# FSITX1_CFG register map
Vendor: Texas Instruments
Peripheral module from a debugger description file (folder am243x).
Registers are 16-bit, read-write, reset values left out (the file's numbers can be read two ways) unless marked. A register's access mark holds for its fields unless they carry their own. Offsets are as the file gives them; lines under a group give offsets from that group; [hi:lo] are bit positions; {n}, {i} and the like mark numbered series; 'fields as' and 'values as' point back to an identical list; <NAME> marks a mode.

## FSITX1_CFG
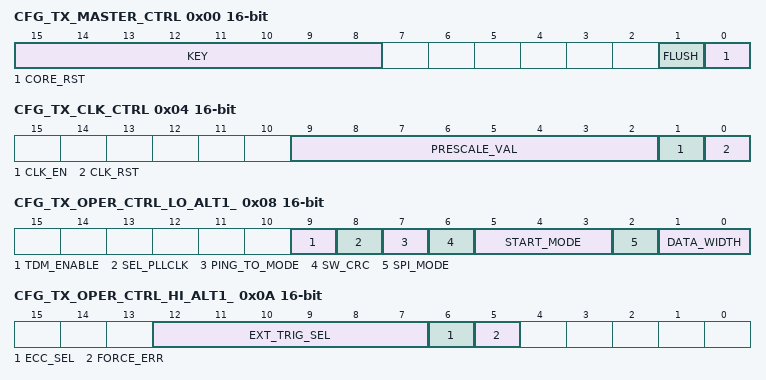
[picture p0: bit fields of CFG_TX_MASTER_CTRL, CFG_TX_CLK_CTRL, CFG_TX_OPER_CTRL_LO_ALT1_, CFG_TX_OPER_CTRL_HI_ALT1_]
0x00 CFG_TX_MASTER_CTRL access per field — Transmit master control register
  [15:8] KEY wo — Write KeyIn order to write to any bit in this register, 0xA5 must be written to this field at the same time. Otherwise, writes are ignored. The key is cleared immediately after writing, so it must be written again for every change to this register.
  [1] FLUSH rw — Flush Operation Start bitThis bit will cause the transmitter to initiate a flush pattern of a single toggle on the TXD0 and TXD1 followed by five full cycles of TXCLK. This bit should be written only when the CORE_RST bit is 0 and the clock to the Transmitter core is turned on. 0h [R/W] = Clear this bit.1h [R/W] = Setting this bit will Initiate flush sequence. To properly execute a flush sequence, Set FLUSH to 1, wait for five TXCLK cycles then clear FLUSH to 0. Note: The KEY field must contain 0xA5 for any write to this bit to take effect. The software must keep this bit set to 1 for at least five TXCLK cycles before setting it back to 0.
  [0] CORE_RST rw — Transmitter Master Core Reset bitThis bit controls the transmitter master core reset. In order to send any frame, this bit must be cleared. 0h [R/W] = Transmitter core is not in reset and can transmit frames.1h [R/W] = Transmitter core is held in reset. Note: The KEY field must contatin 0xA5 for any write to this bit to take effect.
0x02 CFG_Reserved_1 access not given
0x04 CFG_TX_CLK_CTRL — Transmit clock control register. Protected by LOCK field in TX_LOCK_CTRL register.
  [9:2] PRESCALE_VAL — Clock Divider Prescale ValueThe input clock is divided by this 8-bit value and fed into the transmitter core. This divided clock is the rate at which TXCLK will operate. 0h [R/W] = Reserved1h [R/W] = Input clock /12h [R/W] = Input clock /23h [R/W] = Input clock /34h [R/W] = Input clock /4...FFh [R/W] = Input clock /255 TXCLKIN = Input clock / PRESCALE_VALIn FSI mode: TXCLK = TXCLKIN / 2In SPI mode: TXCLK = TXCLKIN
  [1] CLK_EN — Clock Divider Enable bitThis bit will enable and disable the input clock divider and start the clock to the transmitter core. 0h [R/W] = The input clock divider is not enabled and the clock is not connected to the transmitter core.1h [R/W] = The input clock to the transmitter core is being divided by the PRESCALE_VAL and enabled.
  [0] CLK_RST — Clock Divider Reset bitThis bit will reset the clock counter in the clock divider. 0h [R/W] = The clock divider is set based on the value in PRESCALE_VAL. The input clock will be divided by PRESCALE_VAL if CLK_EN is set.1h [R/W] = The clock divider will be reset to 0 and will stay reset until software writes a 0 to this bit.
0x06 CFG_Reserved_2 access not given
0x08 CFG_TX_OPER_CTRL_LO_ALT1_ — Transmit operation control register low. Protected by LOCK field in TX_LOCK_CTRL register.
  [9] TDM_ENABLE — Transmit TDM Mode Enable bit.This bit enables the TDM Mode for multi-slave TDM operation. 0h [R/W] Transmit TDM Mode is not enabled.1h [R/W] Transmit TDM Mode is enabled.
  [8] SEL_PLLCLK — Input Clock Select bitThis bit selects the input clock source for the transmitter core. 0h [R/W] = SYSCLK is the source of the transmitter clock into the clock prescaler.1h [R/W] = PLLRAWCLK is the source of the transmitter core clock into the clock prescaler.
  [7] PING_TO_MODE — Ping Counter Reset Mode Select bitThis bit selects when the ping counter will reset. 0h [R/W] = The ping counter will reset and restart only on hardware initiated ping frames, when ping counter has timed out.1h [R/W] = The ping counter will reset and restart on any software initiated frame as well as a ping counter timeout
  [6] SW_CRC — CRC Source Select bitThis bit selects the source of the CRC value that is transmitted. 0h [R/W] = The transmitted CRC value is computed by hardware.1h [R/W] = The transmitted CRC value is sourced from the value programmed in the TX_USER_CRC register.
  [5:3] START_MODE — Transmission Start Mode Select bitThese bits select the method by which a new frame transmission is started. 0h [R/W] = Only a software write to TX_FRAME_CTRL.START initiate a new transmission.1h [R/W] = The configured external trigger will initiate a new transmission.2h [R/W] = Either writing to TX_FRAME_CTRL.START or the TX_FRAME_TAG_UDATA register will initiate a new transmission. All other combinations of bits are illegal and reserved for future use.
  [2] SPI_MODE — SPI Mode Select bitThis bit enables and disables SPI compatibility mode. 0h [R/W] = FSI is in normal mode of operation.1h [R/W] = FSI is operating in SPI compatibility mode.
  [1:0] DATA_WIDTH — Transmit Data Width Select bitsThese bits define the number of data lines used by the transmitter. 0h [R/W] = Data will be transmitted on one data line [TXD0]1h [R/W] = Data will be transmitted on two data lines [TXD0 and TXD1]. The format of the data is described in the preceeding chapter.2h, 3h [R/W] = Reserved
0x0A CFG_TX_OPER_CTRL_HI_ALT1_ — Transmit operation control register high. Protected by LOCK field in TX_LOCK_CTRL register.
  [12:7] EXT_TRIG_SEL — External Trigger Select bitThese bits define which of the 32 external inputs will be used as the source for the external input trigger. 00h [R/W] = Trigger 1 is the source.01h [R/W] = Trigger 2 is the source.02h [R/W] = Trigger 3 is the source....3Fh [R/W] = Trigger 64 is the source.
  [6] ECC_SEL — ECC Data Width Select bitThis bit selects between 16-bit and 32-bit ECC computation. 0h [R/W] = 32-bit ECC is used.1h [R/W] = 16-bit ECC is used.
  [5] FORCE_ERR — Error Frame Force bitThis bit will force the the CRC value of the transmitted data frame to 0 whenever there is a buffer overrun or underrun condition. This can be used to force a corrupted CRC as the data is not guaranteed to be reliable. The receiver will treat the data as invalid and can handle this as needed.Note: DO NOT use FORCE_ERR if using the SW CRC mode [FSI Transmit]. 0h [R/W] = The CRC will not be forced to 0.1h [R/W] = The CRC will be forced to 0 in a buffer overrun or underrun condition.
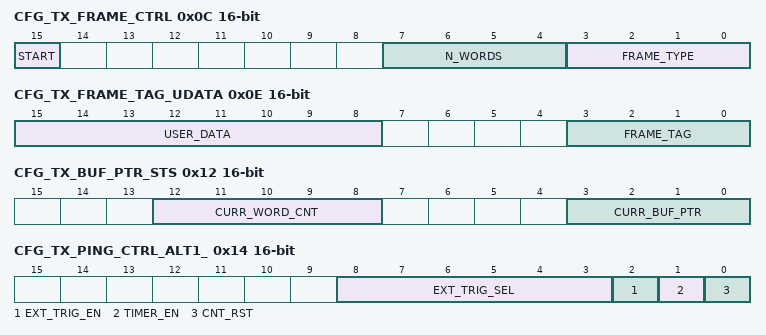
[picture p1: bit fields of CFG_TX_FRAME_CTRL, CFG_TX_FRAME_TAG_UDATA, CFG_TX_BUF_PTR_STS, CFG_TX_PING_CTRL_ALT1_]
0x0C CFG_TX_FRAME_CTRL — Transmit frame control register
  [15] START — Start Transmission bitThis bit will cause the FSI to start transmitting the next frame. 0h [R/W] = Writing a 0 to this bit will have no effect.1h [R/W] = Start the next transmission. This bit will be cleared by hardware.
  [7:4] N_WORDS — Number of Words to be TransmittedThis field defines the number of words which will be transmitted in a DATA_N_WORD frame. This is a user-defined field that must match the corresponding field in the receiver. Set this bitfield to be one less than the number of words to be transmitted. 0h [R/W] = 1 data word frame [16-bit data].1h [R/W] = 2 data word frame [32-bit data]...Fh [R/W] = 16 data word frame [256-bit data].
  [3:0] FRAME_TYPE — Transmit Frame TypeThis field determines the type of frame that will be transmitted next. 0000b [R/W] = Ping Frame. This frame can be sent either by software or automatically by hardware.0100b [R/W] = DATA_1_WORD Frame. One word data frame [16-bit data].0101b [R/W] = DATA_2_WORD Frame. Two word data frame [32-bit data].0110b [R/W] = DATA_4_WORD Frame. Four word data frame [64-bit data]. 0111b [R/W] = DATA_6_WORD Frame. Six word data frame [96-bit data].0011b [R/W] = DATA_N_WORD Frame. The N_WORDS field will determine the number of words [1 to 16] to be sent. Both the transmitter and receiver must have the same value programmed.1111b [R/W] = Error Frame. This frame can be used during error conditions or any condition where the transmitter wants to notify the receiver of a high priorty status. However, the user software is at liberty to use this for any purpose. 0001b, 0010b, and 1000b through 1110b are Reserved and should not be used.
0x0E CFG_TX_FRAME_TAG_UDATA — Transmit frame tag and user data register
  [15:8] USER_DATA — User Data bitsThis is a user-defined value that will be loaded into the the user data phase of the frame. This 8-bit value can be used by the receiver for any application need. This value will not impact any hardware behavior.
  [3:0] FRAME_TAG — This will be used only for software initiated transmissions.Frame tag bitsThis is a user-defined value that will be loaded into the frame tag phase of the next transmission. The receiver may use the frame tag for any application need. This value will not impact any hardware behavior For external triggers do not use this register. Use the TX_PING_TAG register instead.
0x10 CFG_TX_BUF_PTR_LOAD — Transmit buffer pointer control load register
  [3:0] BUF_PTR_LOAD — Buffer Pointer Load bitsThese bits are used to force the transmit buffer pointer to a desired index within the transmit buffer. The next transmission will begin picking data from this index and increment appropriately. This value will be reflected in TX_BUF_PTR_STS only after a minimum 3 SYSCLK cycles + 3 TXCLK cycles. This value should not be written while there is an active transmission as it may corrupt the ongoing frame or other undefined behavior.
0x12 CFG_TX_BUF_PTR_STS ro — Transmit buffer pointer control status register
  [12:8] CURR_WORD_CNT — Words Remaining in the transmit buffer This value indicates the number of words present in the data buffer which have not yet been transmitted. This value is only valid when there is no active transmission. Note: This value will not be valid if there is a buffer overrun or underrun condition.
  [3:0] CURR_BUF_PTR — Current Buffer Pointer IndexThis bitfield will show the current index of the buffer pointer. This value is only valid when there is no active transmission.
0x14 CFG_TX_PING_CTRL_ALT1_ — Transmit ping control register. Protected by LOCK field in TX_LOCK_CTRL register.
  [8:3] EXT_TRIG_SEL — External Trigger Select bitsThis bitfield will select one of the 64 external trigger inputs to as the source to generate a ping frame. A ping frame will only be generated if the EXT_TRIG_EN bit is set. 0h [R/W] = Trigger 1 will be used to generate a ping frame.1h [R/W] = Trigger 2 will be used to generate a ping frame...3Fh [R/W] = Trigger 64 will be used to generate a ping frame.
  [2] EXT_TRIG_EN — External Trigger Enable bitThis bit will allow the external trigger logic to generate a ping frame. 0h [R/W] = External triggers will not be used to generate ping frames.1h [R/W] = The selected external trigger [selected by EXT_TRIG_SEL bits] will be able to generate a ping frame. The ping timer will be ignored if this bit is set.
  [1] TIMER_EN — Ping Timer Enable bitThis bit will enable the ping timer for generating periodic ping frames. 0h [R/W] = The ping timer is disabled and will not generate ping frames.1h [R/W] = The ping timer is enabled and can be used to generate ping frames.Once the timer count reaches the value set by the TX_PING_TO_REF register, it will initiate a ping frame transmission. Note: If the ping timer is used, EXT_TRIG_EN should not be set as it will override this function.
  [0] CNT_RST — Ping Counter Reset bitThis bit will reset the the ping counter to 0. This bit will always be read as 0. 0h [R/W] = Writing a 0 to this bit has no effect.1h [R/W] = The ping counter will be reset to 0.
0x16 CFG_TX_PING_TAG — Transmit ping tag register
  [3:0] TAG — Ping Frame TagThis field contains a 4-bit tag which will be sent in any ping frame that is initiated by an external trigger or the ping timer. This field is user-defined and can be set based on the application requirement. If a ping frame is generated manually, the transmitted tag will be from TX_FRAME_TAG_UDATA.FRAME_TAG, not this value.
0x18 CFG_TX_PING_TO_REF 32-bit — Transmit ping timeout counter reference. Protected by LOCK field in TX_LOCK_CTRL register.
  [31:0] TO_REF — Ping Timer Reference Value.This is the 32-bit reference value for the ping timer. The timer will increment the counter starting from 0. When the reference value is reached, it will generate a timeout event, triggering a ping frame transmission. The counter will then reset to 0 and continue counting.
0x1C CFG_TX_PING_TO_CNT 32-bit ro — Transmit ping timeout current count
  [31:0] TO_CNT — Ping Timer Counter ValueThis register contains the current value of the ping timer counter. After reset, this counter will increment until it reaches the reference value [TX_PING_TO_REF], at which point it generates a ping frame transmission. After this point, the counter will reset to 0 and continue counting. This is a free-running counter
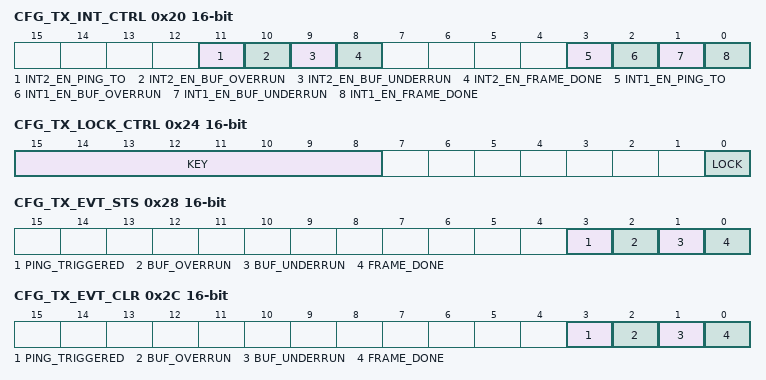
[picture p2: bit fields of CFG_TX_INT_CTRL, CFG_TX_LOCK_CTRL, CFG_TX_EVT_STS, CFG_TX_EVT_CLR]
0x20 CFG_TX_INT_CTRL — Transmit interrupt event control register. Protected by LOCK field in TX_LOCK_CTRL register.
  [11] INT2_EN_PING_TO — Enable PING Timer Interrupt to INT2This bit allows the event to generate an interrupt on the INT2 line. 0h [R/W] = This event will not trigger an interrupt on TX_INT2.1h [R/W] = The ping timer event will trigger an interrupt on TX_INT2.
  [10] INT2_EN_BUF_OVERRUN — Enable Buffer Overrun Interrupt to INT2This bit allows the event to generate an interrupt on the INT2 line. 0h [R/W] = This event will not trigger an interrupt on TX_INT2.1h [R/W] = A Buffer Overrun condition will trigger an interrupt on TX_INT2.
  [9] INT2_EN_BUF_UNDERRUN — Enable Buffer Underrun Interrupt to INT2This bit allows the event to generate an interrupt on the INT2 line. 0h [R/W] = This event will not trigger an interrupt on TX_INT2.1h [R/W] = A Buffer Underrun condition will trigger an interrupt on TX_INT2.
  [8] INT2_EN_FRAME_DONE — Enable Frame Done interrupt to INT2This bit allows the event to generate an interrupt on the INT2 line. 0h [R/W] = This event will not trigger an interrupt on TX_INT2.1h [R/W] = A Frame Done event will trigger an interrupt on TX_INT2.
  [3] INT1_EN_PING_TO — Enable Ping Timer Interrupt to INT1This bit allows the event to generate an interrupt on the INT1 line. 0h [R/W] = This event will not trigger an interrupt on TX_INT1.1h [R/W] = The ping timer event will trigger an interrupt on TX_INT1.
  [2] INT1_EN_BUF_OVERRUN — Enable Buffer Overrun Interrupt to INT1This bit allows the event to generate an interrupt on the INT1 line. 0h [R/W] = This event will not trigger an interrupt on TX_INT1.1h [R/W] = A Buffer Overrun condition will trigger an interrupt on TX_INT1.
  [1] INT1_EN_BUF_UNDERRUN — Enable Buffer Underrun Interrupt to INT1This bit allows the event to generate an interrupt on the INT1 line. 0h [R/W] = This event will not trigger an interrupt on TX_INT1.1h [R/W] = A Buffer Underrun condition will trigger an interrupt on TX_INT1.
  [0] INT1_EN_FRAME_DONE — Enable Frame Done interrupt to INT1This bit allows the event to generate an interrupt on the INT1 line. 0h [R/W] = This event will not trigger an interrupt on TX_INT1.1h [R/W] = A Frame Done event will trigger an interrupt on TX_INT1.
0x22 CFG_TX_DMA_CTRL — Transmit DMA event control register. Protected by LOCK field in TX_LOCK_CTRL register.
  [0] DMA_EVT_EN — DMA Event Enable bitThis bit will enable the DMA event to be generated upon the completion of a transmit frame. 0h [R/W] = A DMA event will not be generated.1h [R/W] = A DMA event will be generated upon the completion of a transmitted frame. Note: The DMA event will only be generated for data frames.
0x24 CFG_TX_LOCK_CTRL access per field — Transmit lock control register
  [15:8] KEY wo — Write KeyIn order to write to this register, 0xA5 must be written to this field at the same time. Otherwise, writes are ignored. The key is cleared immediately after writing, so it must be written again for every change to this register.
  [0] LOCK rw — Control Register Lock Enable bitThis bit locks the contents of all the transmit control registers that support a lock protection. Once locked, further writes will not take effect until a SYSRS has reset this register. Once set, further writes to this bit will be ignored. 0h [R/W] = Transmit control registers can be modified and are not locked.1h [R/W] = Transmit control registers are locked and cannot be modified until this bit is cleared by SYSRS. Any further writes to this bit are ignored. Note: The KEY field must contatin 0xA5 for any write to this bit to take effect.
0x26 CFG_Reserved_3 access not given
0x28 CFG_TX_EVT_STS ro — Transmit event and error status flag register
  [3] PING_TRIGGERED — Ping Frame Triggered Flag BitThis bit indicates that a ping frame has been triggered. This bit is set by hardware when either the ping timer or an external trigger event have occured. Software can also force this bit to get set by writing to the TX_EVT_FRC register. 0h [R] = A ping frame has not been triggered.1h [R] = A ping frame has been triggered by either the ping timer or external trigger. To clear this bit, write to the corresponding bit in the TX_EVT_CLR register.
  [2] BUF_OVERRUN — Buffer Overrun Flag BitThis bit inditcates that buffer overrun has occured.Software can also force this bit to get set by writing to the TX_EVT_FRC register. 0h [R] = Buffer Overrun has not occured.1h [R] = Buffer Overrun has occured. To clear this bit, write to the corresponding bit in the TX_EVT_CLR register.
  [1] BUF_UNDERRUN — Buffer Underrun Flag BitThis bit inditcates that buffer underrun has occured.Software can also force this bit to get set by writing to the TX_EVT_FRC register. 0h [R] = Buffer Underrun has not occured.1h [R] = Buffer Underrun has occured. To clear this bit, write to the corresponding bit in the TX_EVT_CLR register.
  [0] FRAME_DONE — Frame Done Flag BitThis bit inditcates a Frame Done condition. This bit is set by hardware when a frame transmission has been completed. Software can also force this bit to get set by writing to the TX_EVT_FRC register. 0h [R] = Frame Done condition has not occured.1h [R] = Frame Done condition has occured. To clear this bit, write to the corresponding bit in the TX_EVT_CLR register.
0x2A CFG_Reserved_4 access not given
0x2C CFG_TX_EVT_CLR wo — Transmit event and error clear register
  [3] PING_TRIGGERED — Ping Frame Triggered Flag Clear bitThis bit clears the corresponding bit in the TX_EVT_STS register. 0h [W] = Writing a 0 to this bit will have no effect.1h [W] = Writing a 1 to this bit will clear the corresponding bit in the TX_EVT_STS register to 0. Note: This bit may not always be cleared when writing to the corresponding TX_EVT_CLR bit. If PING_TIMEOUT MODE is configured to be 0, a hardware ping timeout may occur when another frame is actively being transmitted. In this case, if this bit still shows as 1 after the clear bit is written then the ping frame has been triggered but not serviced. This bit does not indicate that the ping frame has been completely sent, only that it has been triggered by the timeout event.
  [2] BUF_OVERRUN — Buffer Overrun Flag Clear bitThis bit clears the corresponding bit in the TX_EVT_STS register. 0h [W] = Writing a 0 to this bit will have no effect.1h [W] = Writing a 1 to this bit will clear the corresponding bit in the TX_EVT_STS register to 0.
  [1] BUF_UNDERRUN — Buffer Underrun Flag Clear bitThis bit clears the corresponding bit in the TX_EVT_STS register. 0h [W] = Writing a 0 to this bit will have no effect.1h [W] = Writing a 1 to this bit will clear the corresponding bit in the TX_EVT_STS register to 0.
  [0] FRAME_DONE — Frame Done Flag Clear bitThis bit clears the corresponding bit in the TX_EVT_STS register. 0h [W] = Writing a 0 to this bit will have no effect.1h [W] = Writing a 1 to this bit will clear the corresponding bit in the TX_EVT_STS register to 0.
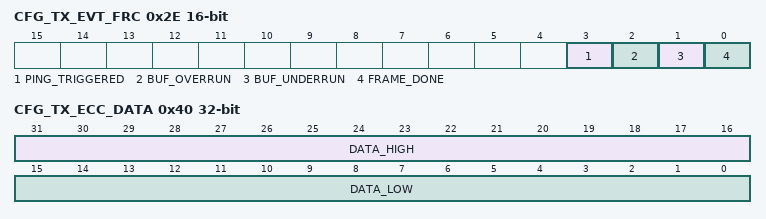
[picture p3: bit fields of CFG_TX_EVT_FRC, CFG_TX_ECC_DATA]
0x2E CFG_TX_EVT_FRC wo — Transmit event and error flag force register
  [3] PING_TRIGGERED — Ping Frame Triggered Flag Force bitThis bit will cause the corresponding bit in the TX_EVT_STS register to get set. The purpose of this register is to allow software to simulate the effect of the event and test the associated software/ISR. 0h [W] = Writing a 0 to this bit will have no effect.1h [W] = Force the corresponding flag bit in the TX_EVT_STS Register.
  [2] BUF_OVERRUN — Buffer Overrun Flag Force bitThis bit will cause the corresponding bit in the TX_EVT_STS register to get set. The purpose of this register is to allow software to simulate the effect of the event and test the associated software/ISR. 0h [R/W] = Writing a 0 to this bit will have no effect.1h [R/W] = Force the corresponding flag bit in the TX_EVT_STS Register.
  [1] BUF_UNDERRUN — Buffer Underrun Flag Force bitThis bit will cause the corresponding bit in the TX_EVT_STS register to get set. The purpose of this register is to allow software to simulate the effect of the event and test the associated software/ISR. 0h [W] = Writing a 0 to this bit will have no effect.1h [W] = Force the corresponding flag bit in the TX_EVT_STS Register.
  [0] FRAME_DONE — Frame Done Flag Force bitThis bit will cause the corresponding bit in the TX_EVT_STS register to get set. The purpose of this register is to allow software to simulate the effect of the event and test the associated software/ISR. 0h [W] = Writing a 0 to this bit will have no effect.1h [W] = Force the corresponding flag bit in the TX_EVT_STS Register.
0x30 CFG_TX_USER_CRC — Transmit user-defined CRC register
  [7:0] USER_CRC — User-defined CRCThis register contains the 8-bit CRC value to be transmitted in the next frame if the transmission is set for user-defined CRC option [TX_OPER_CTRL_LO.SW_CRC = 1]. This register is ignored if the hardware CRC generation is enabled.
0x32 CFG_Reserved_5 access not given
{0x1C+4i} CFG_Reserved_{i} 32-bit access not given (i=6..8)
0x40 CFG_TX_ECC_DATA 32-bit — Transmit ECC data register
  [31:16] DATA_HIGH — Upper 16 bits of ECC DataWriting to this bitfield will cause the ECC logic to compute the ECC[SEC-DED] the entire 32-bit register and update TX_ECC_VAL register with the results. Software should write to these 16 bits of the register in a 32-bit write when needing to compute ECC for 32-bits for the full TX_ECC_DATA register.
  [15:0] DATA_LOW — Lower 16 bits of ECC DataWriting to this bitfield will cause the ECC logic to compute the ECC[SEC-DED] for these 16 bits and update the TX_ECC_VAL register with the results. Software should write to these register bits as a 16-bit write when needing to compute ECC for 16-bits.
0x44 CFG_TX_ECC_VAL ro — Transmit ECC value register
  [6:0] ECC_VAL — Computed ECC ValueThis field contains the ECC value computed using SEC-DED either for 16-bit or 32-bit data in the TX_ECC_DATA register.
0x46 CFG_Reserved_9 access not given
0x80 CFG_TX_BUF_BASE — Base address for transmit buffer
  [15:0] BASE_ADDRESS — Transmit Data Buffer Base AddressThis is the base address of the 16-word data buffer used by the transmitter.
